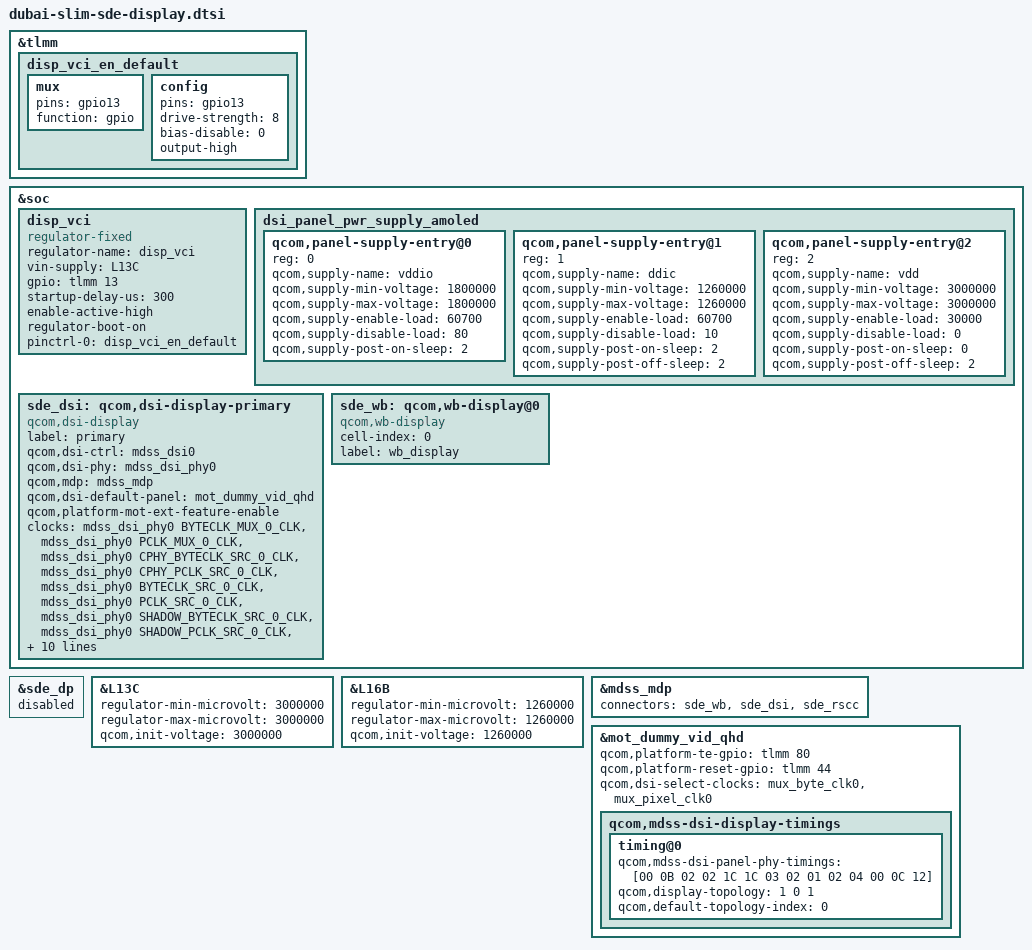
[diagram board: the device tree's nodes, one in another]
#include "dsi-panel-mot-dummy-qhd-video.dtsi"
#include <dt-bindings/clock/mdss-5nm-pll-clk.h>
#include <dt-bindings/clock/qcom,dispcc-yupik.h>

&tlmm {
	disp_vci_en_default: disp_vci_en_default {
		mux {
			pins = "gpio13";
			function = "gpio";
		};

		config {
			pins = "gpio13";
			drive-strength = <8>;
			bias-disable = <0>;
			output-high;
		};
	};
};

&soc {
	disp_vci: disp_vci {
		compatible = "regulator-fixed";
		regulator-name = "disp_vci";
		vin-supply = <&L13C>;
		gpio = <&tlmm 13 0>;
		startup-delay-us = <300>;
		enable-active-high;
		regulator-boot-on;
		pinctrl-names = "default";
		pinctrl-0 = <&disp_vci_en_default>;
	};

	dsi_panel_pwr_supply_amoled: dsi_panel_pwr_supply_amoled {
		#address-cells = <1>;
		#size-cells = <0>;

		qcom,panel-supply-entry@0 {
			reg = <0>;
			qcom,supply-name = "vddio";
			qcom,supply-min-voltage = <1800000>;
			qcom,supply-max-voltage = <1800000>;
			qcom,supply-enable-load = <60700>;
			qcom,supply-disable-load = <80>;
		        qcom,supply-post-on-sleep = <2>;
		};

		qcom,panel-supply-entry@1 {
			reg = <1>;
			qcom,supply-name = "ddic";
			qcom,supply-min-voltage = <1260000>;
			qcom,supply-max-voltage = <1260000>;
			qcom,supply-enable-load = <60700>;
			qcom,supply-disable-load = <10>;
		        qcom,supply-post-on-sleep = <2>;
		        qcom,supply-post-off-sleep = <2>;
		};

		qcom,panel-supply-entry@2 {
			reg = <2>;
			qcom,supply-name = "vdd";
			qcom,supply-min-voltage = <3000000>;
			qcom,supply-max-voltage = <3000000>;
			qcom,supply-enable-load = <30000>;
			qcom,supply-disable-load = <0>;
			qcom,supply-post-on-sleep = <0>;
			qcom,supply-post-off-sleep = <2>;
		};
	};

	sde_dsi: qcom,dsi-display-primary {
		compatible = "qcom,dsi-display";
		label = "primary";

		qcom,dsi-ctrl = <&mdss_dsi0>;
		qcom,dsi-phy = <&mdss_dsi_phy0>;

		qcom,mdp = <&mdss_mdp>;
		qcom,dsi-default-panel = <&mot_dummy_vid_qhd >;
	};
};

&soc {
	sde_wb: qcom,wb-display@0 {
		compatible = "qcom,wb-display";
		cell-index = <0>;
		label = "wb_display";
	};
};

&sde_dp {
	status = "disabled";
};

&sde_dsi {
	qcom,platform-mot-ext-feature-enable;
};

&sde_dsi {
	clocks = <&mdss_dsi_phy0 BYTECLK_MUX_0_CLK>,
			 <&mdss_dsi_phy0 PCLK_MUX_0_CLK>,
			 <&mdss_dsi_phy0 CPHY_BYTECLK_SRC_0_CLK>,
			 <&mdss_dsi_phy0 CPHY_PCLK_SRC_0_CLK>,
			 <&mdss_dsi_phy0 BYTECLK_SRC_0_CLK>,
			 <&mdss_dsi_phy0 PCLK_SRC_0_CLK>,
			 <&mdss_dsi_phy0 SHADOW_BYTECLK_SRC_0_CLK>,
			 <&mdss_dsi_phy0 SHADOW_PCLK_SRC_0_CLK>,
			 <&mdss_dsi_phy0 SHADOW_CPHY_BYTECLK_SRC_0_CLK>,
			 <&mdss_dsi_phy0 SHADOW_CPHY_PCLK_SRC_0_CLK>,
			/*
			 * Currently the dsi clock handles are under the dsi
			 * controller DT node. As soon as the controller probe
			 * finishes, the dispcc sync state can get called before
			 * the dsi_display probe potentially disturbing the clock
			 * votes for cont_splash use case. Hence we are no longer
			 * protected by the component model in this case against the
			 * disp cc sync state getting triggered after the dsi_ctrl
			 * probe. To protect against this incorrect sync state trigger
			 * add this dummy MDP clk vote handle to the dsi_display
			 * DT node. Since the dsi_display driver does not parse
			 * MDP clock nodes, no actual vote shall be added and this
			 * change is done just to satisfy sync state requirements.
			 */
			 <&dispcc DISP_CC_MDSS_MDP_CLK>;
	clock-names = "mux_byte_clk0", "mux_pixel_clk0",
			"cphy_byte_clk0", "cphy_pixel_clk0",
			"src_byte_clk0", "src_pixel_clk0",
			"shadow_byte_clk0", "shadow_pixel_clk0",
			"shadow_cphybyte_clk0", "shadow_cphypixel_clk0",
			"mdp_core_clk";

	pinctrl-names = "panel_active", "panel_suspend";
	pinctrl-0 = <&sde_dsi_active &sde_te_active>;
	pinctrl-1 = <&sde_dsi_suspend &sde_te_suspend>;

	qcom,platform-te-gpio = <&tlmm 80 0>;
	qcom,panel-te-source = <0>;

	vddio-supply = <&L12C>;
	ddic-supply = <&L16B>;
	vdd-supply = <&disp_vci>;

};

&L13C {
	regulator-min-microvolt = <3000000>;
	regulator-max-microvolt = <3000000>;
	qcom,init-voltage = <3000000>;
};

&L16B {
	regulator-min-microvolt = <1260000>;
	regulator-max-microvolt = <1260000>;
	qcom,init-voltage = <1260000>;
};

&mdss_mdp {
	connectors = <&sde_wb &sde_dsi &sde_rscc>;
};


&mot_dummy_vid_qhd {
	qcom,platform-te-gpio = <&tlmm 80 0>;
	qcom,platform-reset-gpio = <&tlmm 44 0>;

	qcom,dsi-select-clocks = "mux_byte_clk0", "mux_pixel_clk0";
	qcom,mdss-dsi-display-timings {
		timing@0 {
			qcom,mdss-dsi-panel-phy-timings = [00 0B 02 02 1C 1C 03
							02 01 02 04 00 0C 12];
			qcom,display-topology = <1 0 1>;
			qcom,default-topology-index = <0>;
		};
	};
};

